# STM32F100xx register map
File version: 1.1
Registers are 32-bit, read-write, reset 0x0 unless marked. A register's access mark holds for its fields unless they carry their own. Offsets are from the block's base; [hi:lo] are bit positions; {n}, {i} and the like mark numbered series.

## RCC — Reset and clock control
Base 0x40021000
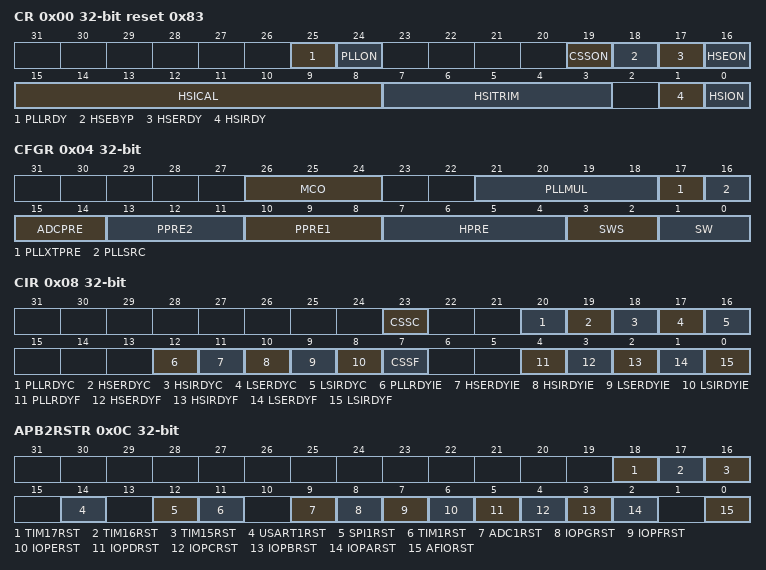
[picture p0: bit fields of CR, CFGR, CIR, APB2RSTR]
0x00 CR access per field reset 0x83 — Clock control register
  [25] PLLRDY ro — PLL clock ready flag
  [24] PLLON rw — PLL enable
  [19] CSSON rw — Clock Security System enable
  [18] HSEBYP rw — External High Speed clock Bypass
  [17] HSERDY ro — External High Speed clock ready flag
  [16] HSEON rw — External High Speed clock enable
  [15:8] HSICAL ro — Internal High Speed clock Calibration
  [7:3] HSITRIM rw — Internal High Speed clock trimming
  [1] HSIRDY ro — Internal High Speed clock ready flag
  [0] HSION rw — Internal High Speed clock enable
0x04 CFGR access per field — Clock configuration register (RCC_CFGR)
  [26:24] MCO rw — Microcontroller clock output
  [21:18] PLLMUL rw — PLL Multiplication Factor
  [17] PLLXTPRE rw — HSE divider for PLL entry
  [16] PLLSRC rw — PLL entry clock source
  [15:14] ADCPRE rw — ADC prescaler
  [13:11] PPRE2 rw — APB High speed prescaler (APB2)
  [10:8] PPRE1 rw — APB Low speed prescaler (APB1)
  [7:4] HPRE rw — AHB prescaler
  [3:2] SWS ro — System Clock Switch Status
  [1:0] SW rw — System clock Switch
0x08 CIR access per field — Clock interrupt register (RCC_CIR)
  [23] CSSC wo — Clock security system interrupt clear
  [20] PLLRDYC wo — PLL Ready Interrupt Clear
  [19] HSERDYC wo — HSE Ready Interrupt Clear
  [18] HSIRDYC wo — HSI Ready Interrupt Clear
  [17] LSERDYC wo — LSE Ready Interrupt Clear
  [16] LSIRDYC wo — LSI Ready Interrupt Clear
  [12] PLLRDYIE rw — PLL Ready Interrupt Enable
  [11] HSERDYIE rw — HSE Ready Interrupt Enable
  [10] HSIRDYIE rw — HSI Ready Interrupt Enable
  [9] LSERDYIE rw — LSE Ready Interrupt Enable
  [8] LSIRDYIE rw — LSI Ready Interrupt Enable
  [7] CSSF ro — Clock Security System Interrupt flag
  [4] PLLRDYF ro — PLL Ready Interrupt flag
  [3] HSERDYF ro — HSE Ready Interrupt flag
  [2] HSIRDYF ro — HSI Ready Interrupt flag
  [1] LSERDYF ro — LSE Ready Interrupt flag
  [0] LSIRDYF ro — LSI Ready Interrupt flag
0x0C APB2RSTR — APB2 peripheral reset register (RCC_APB2RSTR)
  [18] TIM17RST — TIM17 timer reset
  [17] TIM16RST — TIM16 timer reset
  [16] TIM15RST — TIM15 timer reset
  [14] USART1RST — USART1 reset
  [12] SPI1RST — SPI 1 reset
  [11] TIM1RST — TIM1 timer reset
  [9] ADC1RST — ADC 1 interface reset
  [8] IOPGRST — IO port G reset
  [7] IOPFRST — IO port F reset
  [6] IOPERST — IO port E reset
  [5] IOPDRST — IO port D reset
  [4] IOPCRST — IO port C reset
  [3] IOPBRST — IO port B reset
  [2] IOPARST — IO port A reset
  [0] AFIORST — Alternate function I/O reset
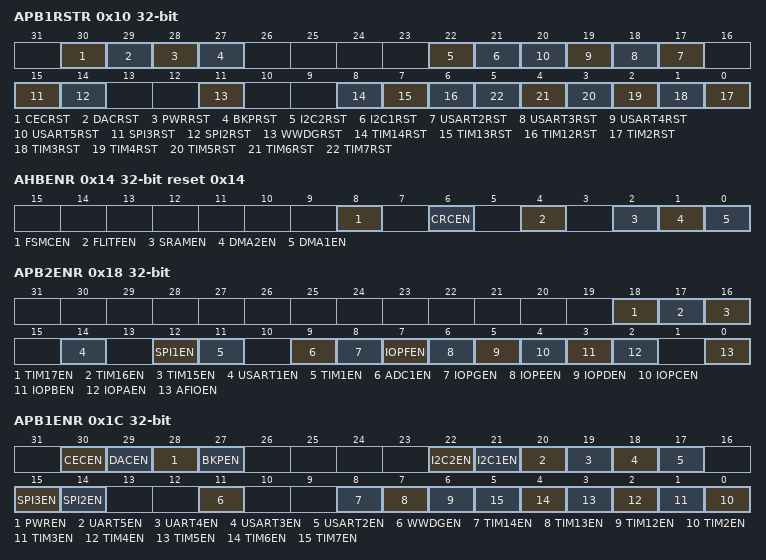
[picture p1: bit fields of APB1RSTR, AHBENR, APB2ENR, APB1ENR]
0x10 APB1RSTR — APB1 peripheral reset register (RCC_APB1RSTR)
  [30] CECRST — CEC reset
  [29] DACRST — DAC interface reset
  [28] PWRRST — Power interface reset
  [27] BKPRST — Backup interface reset
  [22] I2C2RST — I2C2 reset
  [21] I2C1RST — I2C1 reset
  [n+15] USART{n}RST (n=2..5) — USART {n} reset
  [15] SPI3RST — SPI3 reset
  [14] SPI2RST — SPI2 reset
  [11] WWDGRST — Window watchdog reset
  [8] TIM14RST — Timer 14 reset
  [7] TIM13RST — Timer 13 reset
  [6] TIM12RST — Timer 12 reset
  [n-2] TIM{n}RST (n=2..7) — Timer {n} reset
0x14 AHBENR reset 0x14 — AHB Peripheral Clock enable register (RCC_AHBENR)
  [8] FSMCEN — FSMC clock enable
  [6] CRCEN — CRC clock enable
  [4] FLITFEN — FLITF clock enable
  [2] SRAMEN — SRAM interface clock enable
  [1] DMA2EN — DMA2 clock enable
  [0] DMA1EN — DMA1 clock enable
0x18 APB2ENR — APB2 peripheral clock enable register (RCC_APB2ENR)
  [all] fields
    0=Disabled; 1=Enabled
  [18] TIM17EN — TIM17 Timer clock enable
  [17] TIM16EN — TIM16 Timer clock enable
  [16] TIM15EN — TIM15 Timer clock enable
  [14] USART1EN — USART1 clock enable
  [12] SPI1EN — SPI 1 clock enable
  [11] TIM1EN — TIM1 Timer clock enable
  [9] ADC1EN — ADC 1 interface clock enable
  [8] IOPGEN — I/O port G clock enable
  [7] IOPFEN — I/O port F clock enable
  [6] IOPEEN — I/O port E clock enable
  [5] IOPDEN — I/O port D clock enable
  [4] IOPCEN — I/O port C clock enable
  [3] IOPBEN — I/O port B clock enable
  [2] IOPAEN — I/O port A clock enable
  [0] AFIOEN — Alternate function I/O clock enable
0x1C APB1ENR — APB1 peripheral clock enable register (RCC_APB1ENR)
  [all] fields
    0=Disabled; 1=Enabled
  [30] CECEN — CEC clock enable
  [29] DACEN — DAC interface clock enable
  [28] PWREN — Power interface clock enable
  [27] BKPEN — Backup interface clock enable
  [22] I2C2EN — I2C 2 clock enable
  [21] I2C1EN — I2C 1 clock enable
  [20] UART5EN — UART 5 clock enable
  [19] UART4EN — UART 4 clock enable
  [18] USART3EN — USART 3 clock enable
  [17] USART2EN — USART 2 clock enable
  [15] SPI3EN — SPI 3 clock enable
  [14] SPI2EN — SPI 2 clock enable
  [11] WWDGEN — Window watchdog clock enable
  [8] TIM14EN — Timer 14 clock enable
  [7] TIM13EN — Timer 13 clock enable
  [6] TIM12EN — Timer 12 clock enable
  [n-2] TIM{n}EN (n=2..7) — Timer {n} clock enable
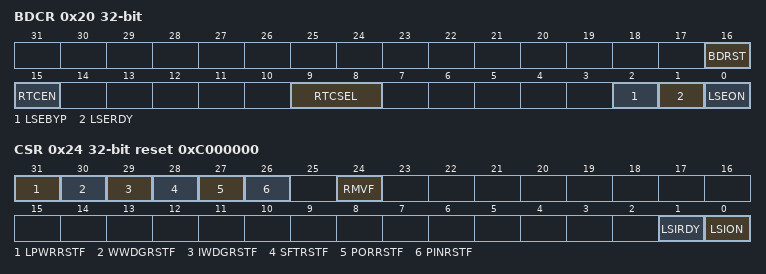
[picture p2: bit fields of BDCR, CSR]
0x20 BDCR access per field — Backup domain control register (RCC_BDCR)
  [16] BDRST rw — Backup domain software reset
  [15] RTCEN rw — RTC clock enable
  [9:8] RTCSEL rw — RTC clock source selection
  [2] LSEBYP rw — External Low Speed oscillator bypass
  [1] LSERDY ro — External Low Speed oscillator ready
  [0] LSEON rw — External Low Speed oscillator enable
0x24 CSR access per field reset 0xC000000 — Control/status register (RCC_CSR)
  [31] LPWRRSTF rw — Low-power reset flag
  [30] WWDGRSTF rw — Window watchdog reset flag
  [29] IWDGRSTF rw — Independent watchdog reset flag
  [28] SFTRSTF rw — Software reset flag
  [27] PORRSTF rw — POR/PDR reset flag
  [26] PINRSTF rw — PIN reset flag
  [24] RMVF rw — Remove reset flag
  [1] LSIRDY ro — Internal low speed oscillator ready
  [0] LSION rw — Internal low speed oscillator enable
0x2C CFGR2 — Clock configuration register 2
  [3:0] PREDIV1 — PREDIV1 division factor
